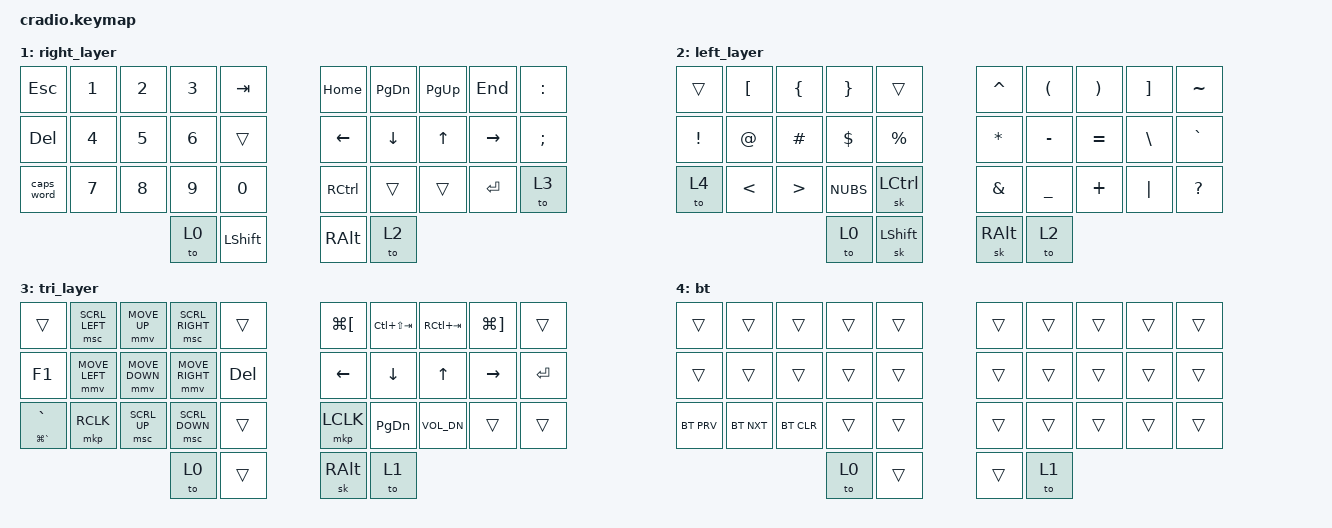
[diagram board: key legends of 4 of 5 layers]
// Copyright (c) 2022 The ZMK Contributors
// SPDX-License-Identifier: MIT

#include <behaviors.dtsi>
#include <dt-bindings/zmk/keys.h>
#include <dt-bindings/zmk/bt.h>
#include <dt-bindings/zmk/mouse.h>


&mt {
    flavor = "tap-preferred";
    tapping_term_ms = <200>;
};

&mmv {
   time-to-max-speed-ms = <680>;
   acceleration-exponent=<2>;
};

// Home row mods macro
#define HRML(k1,k2,k3,k4) &ht LSHFT k1  &ht LALT k2  &ht LCTRL k3  &ht LGUI k4
#define HRMR(k1,k2,k3,k4) &ht RGUI k1  &ht RCTRL k2  &ht RALT k3  &ht RSHFT k4

/ {
    behaviors {
        ht: hold_tap {
            compatible = "zmk,behavior-hold-tap";
            #binding-cells = <2>;
            flavor = "tap-preferred";
            tapping-term-ms = <220>;
            quick-tap-ms = <150>;
            require-prior-idle-ms = <100>;
            bindings = <&kp>, <&kp>;
            display-name = "Hold-Tap";
        };
        td: tapdance {
            compatible = "zmk,behavior-hold-tap";
            label = "TAPDANCE";
            #binding-cells = <2>;
            tapping-term-ms = <150>;
            quick_tap_ms = <0>;
            flavor = "tap-preferred";
            bindings = <&kp>, <&kp>;
            display-name = "Tap-Dance";
        };
    };

    keymap {
        compatible = "zmk,keymap";
        default_layer {
            bindings = <
        //╭──────────┬──────────┬──────────┬──────────┬──────────╮   ╭──────────┬──────────┬──────────┬──────────┬──────────╮
        //│  Q       │  W       │  F       │  P       │  B       │   │  J       │  L       │  U       │  Y       │  BSPC    │
            &kp Q      &kp W      &kp F      &kp P      &kp B          &kp J      &kp L      &kp U      &kp Y      &kp BSPC
        //├──────────┼──────────┼──────────┼──────────┼──────────┤   ├──────────┼──────────┼──────────┼──────────┼──────────┤
        //│  A       │  R       │  S       │  T       │  G       │   │  M       │  N       │  E       │  I       │ O      │
            HRML(A,        R,         S,         T)     &kp G          &kp M      HRMR(N,        E,         I,        O)
        //├──────────┼──────────┼──────────┼──────────┼──────────┤   ├──────────┼──────────┼──────────┼──────────┼──────────┤
        //│  Z       │  X       │  C       │  D       │  V       │   │  K       │  H       │ , <      │ . >      │ / ?      │
            &kp Z      &kp X      &kp C      &kp D      &kp V          &kp K      &kp H   &td MINUS COMMA &td EXCL DOT  &td UNDER FSLH
        //╰──────────┴──────────┴──────────┼──────────┼──────────┤   ├──────────┼──────────┼──────────┴──────────┴──────────╯
                                 &mt LC(LS(LALT)) SPC   &sk LSHIFT    &sk RCTRL  &to 1
        //                                 ╰──────────┴──────────╯   ╰──────────┴──────────╯
            >;
        };

        right_layer {
            bindings = <
        //╭──────────┬──────────┬──────────┬──────────┬──────────╮   ╭──────────┬──────────┬──────────┬──────────┬──────────╮
        //│ ESCAPE   │          │          │          │          │   │ HOME     │ PAGE DN  │ PAGE UP  │ END      │  :       │
            &kp ESC    &kp N1     &kp N2     &kp N3     &kp TAB         &kp HOME   &kp PG_DN  &kp PG_UP  &kp END    &kp COLON
        //├──────────┼──────────┼──────────┼──────────┼──────────┤   ├──────────┼──────────┼──────────┼──────────┼──────────┤
        //│ DELETE   │          │          │          │          │   │ LEFT     │ DOWN     │ UP       │ RIGHT    │  ;       │
            &kp DEL    &kp N4     &kp N5     &kp N6     &trans         &kp LEFT   &kp DOWN   &kp UP   &kp RIGHT   &kp SEMI
        //├──────────┼──────────┼──────────┼──────────┼──────────┤   ├──────────┼──────────┼──────────┼──────────┼──────────┤
        //│ CAPS     │          │          │          │          │   │          │          │          │          │          │
           &caps_word  &kp N7     &kp N8     &kp N9     &kp N0         &kp RCTRL  &trans     &trans     &kp ENTER    &to 3
        //╰──────────┴──────────┴──────────┼──────────┼──────────┤   ├──────────┼──────────┼──────────┴──────────┴──────────╯
                                             &to 0     &kp LSHIFT     &kp RALT     &to 2
        //                                 ╰──────────┴──────────╯   ╰──────────┴──────────╯
            >;
        };

        left_layer {
            bindings = <
        //╭──────────┬──────────┬──────────┬──────────┬──────────╮   ╭──────────┬──────────┬──────────┬──────────┬──────────╮
        //│          │  [       │  {       │  }       │          │   │  ^       │  (       │  )       │  ]       │  ~       │
            &trans     &kp LBKT   &kp LBRC   &kp RBRC   &trans         &kp CARET  &kp LPAR   &kp RPAR   &kp RBKT   &kp TILDE
        //├──────────┼──────────┼──────────┼──────────┼──────────┤   ├──────────┼──────────┼──────────┼──────────┼──────────┤
        //│  !       │  @       │  #       │  $       │  %       │   │  *       │  -       │  =       │  \       │  `       │
            &kp EXCL   &kp AT     &kp HASH   &kp DLLR   &kp PRCNT      &kp ASTRK  &kp MINUS  &kp EQUAL  &kp BSLH   &kp GRAVE
        //├──────────┼──────────┼──────────┼──────────┼──────────┤   ├──────────┼──────────┼──────────┼──────────┼──────────┤
        //│          │          │          │          │          │   │  &       │  _       │  +       │  │       │          │
            &to 4     &kp LT     &kp GT     &kp NUBS     &sk LCTRL         &kp AMPS   &kp UNDER  &kp PLUS   &kp PIPE   &kp QMARK
        //╰──────────┴──────────┴──────────┼──────────┼──────────┤   ├──────────┼──────────┼──────────┴──────────┴──────────╯
                                             &to 0     &sk LSHIFT         &sk RALT     &to 2
        //                                 ╰──────────┴──────────╯   ╰──────────┴──────────╯
            >;
        };

		tri_layer {
		bindings = <
		&trans  &msc SCRL_LEFT    &mmv MOVE_UP    &msc SCRL_RIGHT    &trans 			&kp LG(LBKT)   &kp LC(LS(TAB))   &kp RC(TAB) &kp LG(RBKT) &trans
		&kp F1 &mmv MOVE_LEFT &mmv MOVE_DOWN &mmv MOVE_RIGHT &kp DEL  						&kp LEFT &kp DOWN  &kp UP &kp RIGHT &kp ENTER 
		&td LG(GRAVE) GRAVE &mkp RCLK  &msc SCRL_UP &msc SCRL_DOWN &trans   				&mkp LCLK &kp PG_DN  &kp K_VOL_DN  &trans &trans   
					 &to 0 &trans  					&sk RALT &to 1 
		>;
		};	

        bt {
		bindings = <
		&trans  &trans &trans &trans &trans &trans &trans &trans &trans &trans 
		&trans  &trans &trans &trans &trans &trans &trans &trans &trans &trans 
		&bt BT_PRV  &bt BT_NXT &bt BT_CLR &trans &trans   				&trans &trans  &trans  &trans &trans   
					 &to 0 &trans  					&trans &to 1 
		>;
		};
    };
};
